# RN831X_RN861X_MCU register map
File version: v0.0.1
CPU: RN831X_RN861X_MCU r1p0, little endian, MPU, no FPU
Registers are 32-bit, read-write, reset 0x0 unless marked. A register's access mark holds for its fields unless they carry their own. Offsets are from the block's base; [hi:lo] are bit positions; {n}, {i} and the like mark numbered series.

## FLASH_CORE0 — FLASH Module core0
Base 0x30000000
Same registers: FLASH_CORE1 0xB0000000
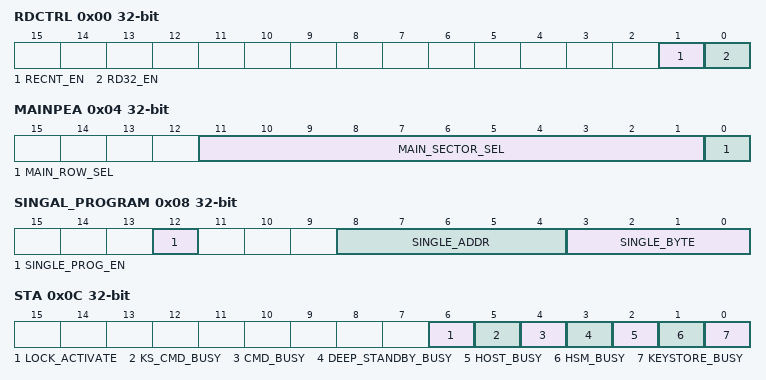
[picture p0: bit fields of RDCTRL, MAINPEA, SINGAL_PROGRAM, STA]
0x00 RDCTRL — Read Mode Control Register
  [1] RECNT_EN — RE_CNT operation control
  [0] RD32_EN — 32-byte read enable
0x04 MAINPEA — MAIN Address Config Register
  [11:1] MAIN_SECTOR_SEL — Selected row in sector
  [0] MAIN_ROW_SEL — Selected sector index
0x08 SINGAL_PROGRAM — Byte Program Register
  [12] SINGLE_PROG_EN — Single-byte programming mode
  [8:4] SINGLE_ADDR — Programming address (lower 5 bits of flash address)
  [3:0] SINGLE_BYTE — Byte select
0x0C STA — Status Register
  [6] LOCK_ACTIVATE — Lock mechanism status
  [5] KS_CMD_BUSY — Keystore command busy
  [4] CMD_BUSY — Command busy (FLASH_CMD)
  [3] DEEP_STANDBY_BUSY — Deep standby status
  [2] HOST_BUSY — Controller busy (host commands)
  [1] HSM_BUSY — Controller busy (HSM commands)
  [0] KEYSTORE_BUSY — Controller busy (keystore commands)
0x10 RECNT1 access not given — FLASH Access Counter1
  [31:0] RECNT1 — Lower 32 bits of read counter
0x14 RECNT2 access not given — FLASH Access Counter2
  [31:0] RECNT2 — Upper 32 bits of read counter
0x18 PSW access not given — Password Register
  [15:0] PSW — Unlock password
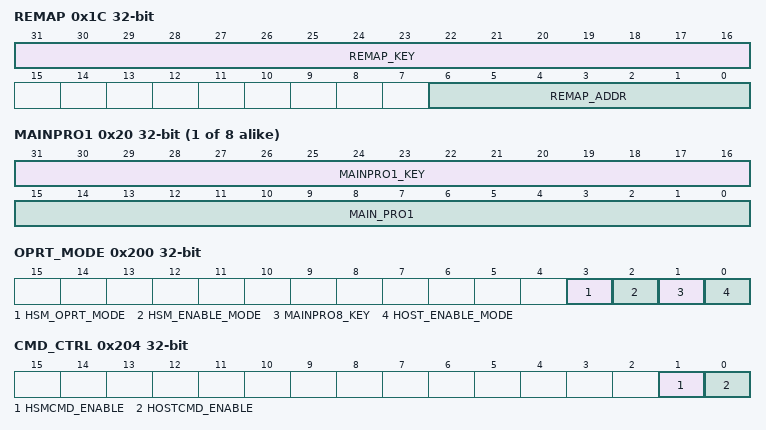
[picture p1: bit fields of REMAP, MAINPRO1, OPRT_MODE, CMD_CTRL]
0x1C REMAP — Address Remap Register
  [31:16] REMAP_KEY — Command key (effective only with valid FLASH_PSW)
  [6:0] REMAP_ADDR — Remap address (8KB granularity, effective when remap_en=1)
{0x1C+4i} MAINPRO{i} (i=1..8) — Write Protection Register{i}
  [31:16] MAINPRO{i}_KEY — Protection key (requires valid FLASH_PSW)
  [15:0] MAIN_PRO{i} — 8KB sector protection (bit0=sector0, bit1=sector1, etc.), 0: Protected (no erase/write), 1: Allow erase/write
{0x100+4i} PG_DATA{i} access not given (i=0..63) — Program Data Register{i}
  [31:0] NVR_PG_DATA — Programming data buffer{i}, (64-bit word = {PG_DATA[n+1], PG_DATA[n]})
0x200 OPRT_MODE — Operation Mode Register
  [3] HSM_OPRT_MODE — HSM operation mode
  [2] HSM_ENABLE_MODE — HSM command enable mode
  [1] MAINPRO8_KEY — Host operation mode
  [0] HOST_ENABLE_MODE — Host command enable mode
0x204 CMD_CTRL — Command Control Register
  [1] HSMCMD_ENABLE — HSM command enable
  [0] HOSTCMD_ENABLE — Host command enable
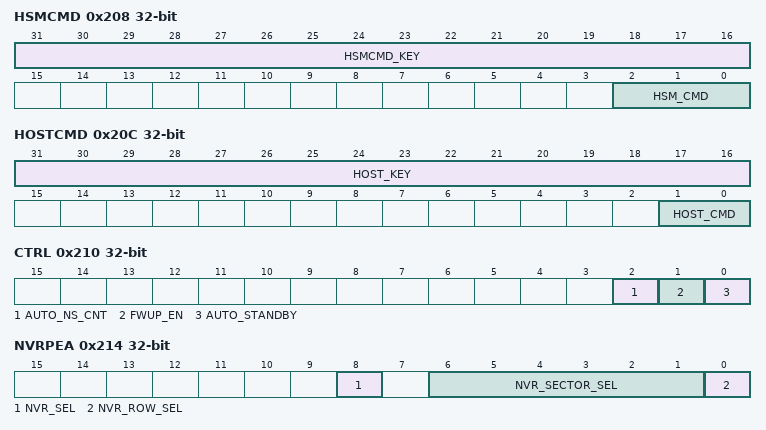
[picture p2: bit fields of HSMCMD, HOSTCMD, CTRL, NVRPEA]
0x208 HSMCMD — HSM Command Register
  [31:16] HSMCMD_KEY — Command key (0xC362 to activate)
  [2:0] HSM_CMD — Command encoding
0x20C HOSTCMD — Host Command Register
  [31:16] HOST_KEY — Command key (0x2ADC to activate)
  [1:0] HOST_CMD — Command encoding
0x210 CTRL — Control Register
  [2] AUTO_NS_CNT — 1μs timer source
  [1] FWUP_EN — Deep standby wakeup
  [0] AUTO_STANDBY — Standby control
0x214 NVRPEA — Address Config Register
  [8] NVR_SEL — Flash area selection
  [6:1] NVR_SECTOR_SEL — NVR sector index (0=first sector, etc.)
  [0] NVR_ROW_SEL — Row index in sector (0=first row, etc.)
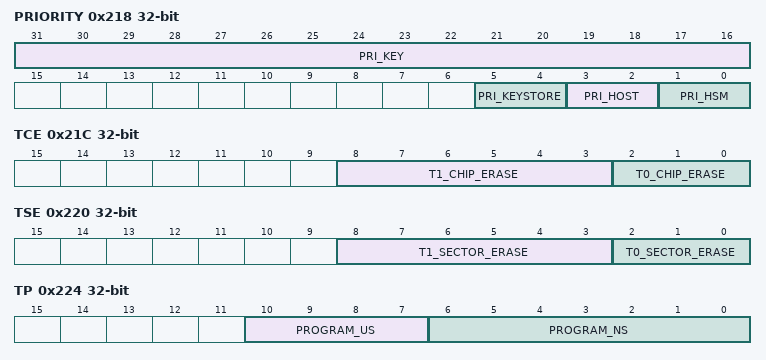
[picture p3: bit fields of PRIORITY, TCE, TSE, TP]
0x218 PRIORITY — Priority Control Register
  [31:16] PRI_KEY — Configuration key (0x6F2C to activate)
  [5:4] PRI_KEYSTORE — Keystore priority
  [3:2] PRI_HOST — Host priority
  [1:0] PRI_HSM — HSM priority
0x21C TCE — Chip Erase Timing Register
  [8:3] T1_CHIP_ERASE — Chip erase time - integer ms
  [2:0] T0_CHIP_ERASE — Fractional ms (0.128ms units)
0x220 TSE — Sector Erase Timing Register
  [8:3] T1_SECTOR_ERASE — Sector erase - integer ms
  [2:0] T0_SECTOR_ERASE — Fractional ms
0x224 TP — Program Timing Register
  [10:7] PROGRAM_US — Program time - integer μs
  [6:0] PROGRAM_NS — Fractional μs
0x228 TUS access not given — Microsecond Timing Register
  [6:0] US_UNIT — Clock cycles per 1μs
0x22C TW access not given — Wait Time Register
  [2:0] FLASH_RD_WAIT — Read wait cycle configuration
0x230 READONLY access not given — Read-Only Control Register
  [7:0] READ_ONLY_EN — Security lock control
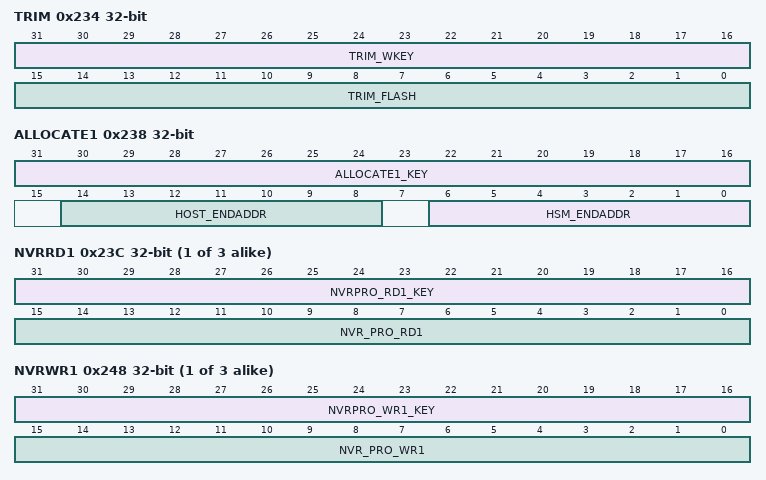
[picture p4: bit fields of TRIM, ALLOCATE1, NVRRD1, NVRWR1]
0x234 TRIM — Calibration Register
  [31:16] TRIM_WKEY — Write key (0xD0A3 enables writes)
  [15:0] TRIM_FLASH — Calibration control
0x238 ALLOCATE1 — Region Allocation Register
  [31:16] ALLOCATE1_KEY — Config key (0xABA3 with ALLOCATE1_LOCK=0x6A)
  [14:8] HOST_ENDADDR — N300 accessible end address
  [6:0] HSM_ENDADDR — N200 accessible end address
{0x238+4i} NVRRD{i} (i=1..3) — NVR Read Permission Register{i}
  [31:16] NVRPRO_RD{i}_KEY — Key (0x63DA)
  [15:0] NVR_PRO_RD{i} — Sector 0-15 read enable
{0x244+4i} NVRWR{i} (i=1..3) — NVR Write Permission Register{i}
  [31:16] NVRPRO_WR{i}_KEY — Key (0x63DA)
  [15:0] NVR_PRO_WR{i} — Sector 0-15 write enable
0x254 ALLOCATE1_LOCK access not given — Allocation Lock Register
  [7:0] ALLOCATE1_LOCK — Write any value clears to 0x00, Only writable when value=0x6A
0x258 CHIPERASE_PSW access not given — Lifecycle Management Register
  [7:0] CHIPERASE_PSW — Enable value (0x6D) for chip erase
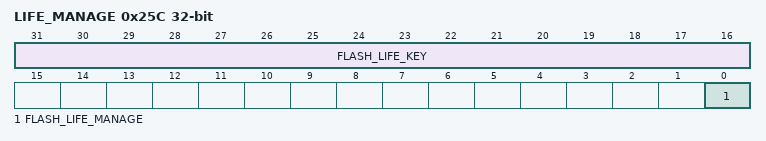
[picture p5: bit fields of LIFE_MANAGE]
0x25C LIFE_MANAGE — Lifecycle Lock Register
  [31:16] FLASH_LIFE_KEY — Key (0x12CD)
  [0] FLASH_LIFE_MANAGE — Sector 47 control
0x260 LIFE_MANAGE_LOCK access not given
  [7:0] LIFE_MANAGE_LOCK — Write any value clears to 0x00, Only writable when value=0x73
